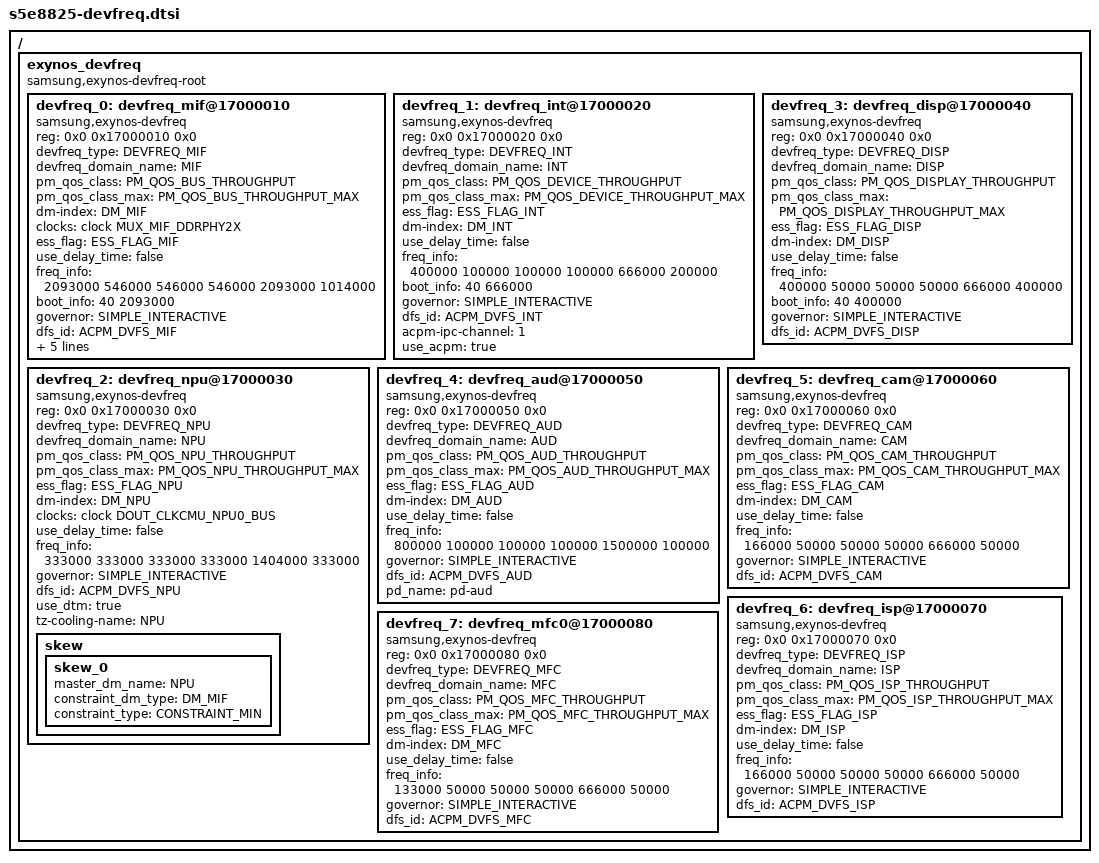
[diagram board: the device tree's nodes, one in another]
/*
 * SAMSUNG S5E8825 SoC DVFS Manager device tree source
 *
 * Copyright (c) 2021 Samsung Electronics Co., Ltd.
 *		http://www.samsung.com
 *
 * SAMSUNG S5E8825 SoC device nodes are listed in this file.
 * EXYNOS based board files can include this file and provide
 * values for board specfic bindings.
 *
 * This program is free software; you can redistribute it and/or modify
 * it under the terms of the GNU General Public License version 2 as
 * published by the Free Software Foundation.
 */

/ {
	exynos_devfreq {
		compatible = "samsung,exynos-devfreq-root";
		#address-cells = <2>;
		#size-cells = <1>;
		ranges;
		devfreq_0: devfreq_mif@17000010 {
			compatible = "samsung,exynos-devfreq";
			reg = <0x0 0x17000010 0x0>;
			devfreq_type = <DEVFREQ_MIF>;
			devfreq_domain_name = "MIF";
			pm_qos_class = <PM_QOS_BUS_THROUGHPUT>;
			pm_qos_class_max = <PM_QOS_BUS_THROUGHPUT_MAX>;
			dm-index = <DM_MIF>;
			clocks = <&clock MUX_MIF_DDRPHY2X>;
			clock-names = "DEVFREQ";
			ess_flag = <ESS_FLAG_MIF>;

			/* Delay time */
			use_delay_time = "false";

			freq_info = <2093000 546000 546000 546000 2093000 1014000>;
			/* initial_freq, default_qos, suspend_freq, min_freq, max_freq reboot_freq */

			/* Booting value */
			boot_info = <40 2093000>;
			/* boot_qos_timeout, boot_freq */

			/* governor data */
			governor = <SIMPLE_INTERACTIVE>;

			dfs_id = <ACPM_DVFS_MIF>;
			acpm-ipc-channel = <1>;
			use_acpm = "true";
			update_fvp = "true";

			use_migov = "true";

			sysbusy = "true";
		};

		devfreq_1: devfreq_int@17000020 {
			compatible = "samsung,exynos-devfreq";
			reg = <0x0 0x17000020 0x0>;
			devfreq_type = <DEVFREQ_INT>;
			devfreq_domain_name = "INT";
			pm_qos_class = <PM_QOS_DEVICE_THROUGHPUT>;
			pm_qos_class_max = <PM_QOS_DEVICE_THROUGHPUT_MAX>;
			ess_flag = <ESS_FLAG_INT>;
			dm-index = <DM_INT>;

			/* Delay time */
			use_delay_time = "false";

			freq_info = <400000 100000 100000 100000 666000 200000>;
			/* <initial_freq, default_qos, suspend_freq, min, max, reboot_freq> */

			/* Booting value */
			boot_info = <40 666000>;
			/* boot_qos_timeout, boot_freq */

			/* governor data */
			governor = <SIMPLE_INTERACTIVE>;

			dfs_id = <ACPM_DVFS_INT>;
			acpm-ipc-channel = <1>;
			use_acpm = "true";
		};

		devfreq_2: devfreq_npu@17000030 {
			compatible = "samsung,exynos-devfreq";
			reg = <0x0 0x17000030 0x0>;
			devfreq_type = <DEVFREQ_NPU>;
			devfreq_domain_name = "NPU";
			pm_qos_class = <PM_QOS_NPU_THROUGHPUT>;
			pm_qos_class_max = <PM_QOS_NPU_THROUGHPUT_MAX>;
			ess_flag = <ESS_FLAG_NPU>;
			dm-index = <DM_NPU>;
			clocks = <&clock DOUT_CLKCMU_NPU0_BUS>;
			clock-names = "DEVFREQ";

			/* Delay time */
			use_delay_time = "false";

			freq_info = <333000 333000 333000 333000 1404000 333000>;
			/* <initial, default_qos, suspend_freq, min, max, reboot_freq> */

			/* governor data */
			governor = <SIMPLE_INTERACTIVE>;

			dfs_id = <ACPM_DVFS_NPU>;

			use_dtm = "true";
			#cooling-cells = <2>;
			tz-cooling-name = "NPU";

			skew {
				skew_0 {
					master_dm_name = "NPU";
					constraint_dm_type = <DM_MIF>;
					constraint_type = <CONSTRAINT_MIN>;
				};
			};

		};


		devfreq_3: devfreq_disp@17000040 {
			compatible = "samsung,exynos-devfreq";
			reg = <0x0 0x17000040 0x0>;
			devfreq_type = <DEVFREQ_DISP>;
			devfreq_domain_name = "DISP";
			pm_qos_class = <PM_QOS_DISPLAY_THROUGHPUT>;
			pm_qos_class_max = <PM_QOS_DISPLAY_THROUGHPUT_MAX>;
			ess_flag = <ESS_FLAG_DISP>;
			dm-index = <DM_DISP>;

			/* Delay time */
			use_delay_time = "false";

			freq_info = <400000 50000 50000 50000 666000 400000>;
			/* <initial_freq, default_qos, suspend_freq, min, max, reboot_freq> */

			/* Booting value */
			boot_info = <40 400000>;
			/* boot_qos_timeout, boot_freq */

			/* governor data */
			governor = <SIMPLE_INTERACTIVE>;

			dfs_id = <ACPM_DVFS_DISP>;
		};


		devfreq_4: devfreq_aud@17000050 {
			compatible = "samsung,exynos-devfreq";
			reg = <0x0 0x17000050 0x0>;
			devfreq_type = <DEVFREQ_AUD>;
			devfreq_domain_name = "AUD";
			pm_qos_class = <PM_QOS_AUD_THROUGHPUT>;
			pm_qos_class_max = <PM_QOS_AUD_THROUGHPUT_MAX>;
			ess_flag = <ESS_FLAG_AUD>;
			dm-index = <DM_AUD>;

			/* Delay time */
			use_delay_time = "false";

			freq_info = <800000 100000 100000 100000 1500000 100000>;
			/* <initial, default_qos, suspend_freq, min, max, reboot_freq> */

			/* governor data */
			governor = <SIMPLE_INTERACTIVE>;

			dfs_id = <ACPM_DVFS_AUD>;

			pd_name = "pd-aud";
		};

		devfreq_5: devfreq_cam@17000060 {
			compatible = "samsung,exynos-devfreq";
			reg = <0x0 0x17000060 0x0>;
			devfreq_type = <DEVFREQ_CAM>;
			devfreq_domain_name = "CAM";
			pm_qos_class = <PM_QOS_CAM_THROUGHPUT>;
			pm_qos_class_max = <PM_QOS_CAM_THROUGHPUT_MAX>;
			ess_flag = <ESS_FLAG_CAM>;
			dm-index = <DM_CAM>;
			/* Delay time */
			use_delay_time = "false";

			freq_info = <166000 50000 50000 50000 666000 50000>;
			/* <initial, default_qos, suspend_freq, min, max, reboot_freq> */

			/* governor data */
			governor = <SIMPLE_INTERACTIVE>;

			dfs_id = <ACPM_DVFS_CAM>;
		};

		devfreq_6: devfreq_isp@17000070 {
			compatible = "samsung,exynos-devfreq";
			reg = <0x0 0x17000070 0x0>;
			devfreq_type = <DEVFREQ_ISP>;
			devfreq_domain_name = "ISP";
			pm_qos_class = <PM_QOS_ISP_THROUGHPUT>;
			pm_qos_class_max = <PM_QOS_ISP_THROUGHPUT_MAX>;
			ess_flag = <ESS_FLAG_ISP>;
			dm-index = <DM_ISP>;

			/* Delay time */
			use_delay_time = "false";

			freq_info = <166000 50000 50000 50000 666000 50000>;
			/* <initial, default_qos, suspend_freq, min, max, reboot_freq> */

			/* governor data */
			governor = <SIMPLE_INTERACTIVE>;

			dfs_id = <ACPM_DVFS_ISP>;
		};

		devfreq_7: devfreq_mfc0@17000080 {
			compatible = "samsung,exynos-devfreq";
			reg = <0x0 0x17000080 0x0>;
			devfreq_type = <DEVFREQ_MFC>;
			devfreq_domain_name = "MFC";
			pm_qos_class = <PM_QOS_MFC_THROUGHPUT>;
			pm_qos_class_max = <PM_QOS_MFC_THROUGHPUT_MAX>;
			ess_flag = <ESS_FLAG_MFC>;
			dm-index = <DM_MFC>;

			/* Delay time */
			use_delay_time = "false";

			freq_info = <133000 50000 50000 50000 666000 50000>;
			/* <initial, default_qos, suspend_freq, min, max, reboot_freq> */

			/* governor data */
			governor = <SIMPLE_INTERACTIVE>;

			dfs_id = <ACPM_DVFS_MFC>;
		};
	};
};
